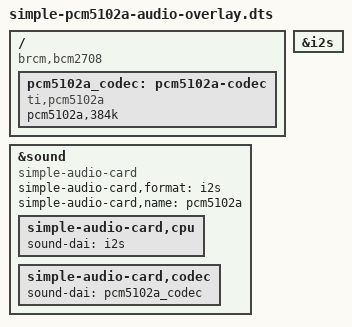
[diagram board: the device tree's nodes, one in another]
// Definitions for a generic board or HAT using TI PCM510x DAC
/dts-v1/;
/plugin/;

/ {
	compatible = "brcm,bcm2708";

	fragment@0 {
		target = <&i2s>;
		__overlay__ {
			status = "okay";
		};
	};

	fragment@1 {
		target-path = "/";
		__overlay__ {
			pcm5102a_codec: pcm5102a-codec {
				#sound-dai-cells = <0>;
				compatible = "ti,pcm5102a";
				pcm5102a,384k;
				status = "okay";
			};
		};
	};

	fragment@2 {
		target = <&sound>;
		simple_audio_card: __overlay__ {
			compatible = "simple-audio-card";
			simple-audio-card,format = "i2s";
			simple-audio-card,name = "pcm5102a";
			status = "okay";
			simple-audio-card,cpu {
				sound-dai = <&i2s>;
			};
			simple-audio-card,codec {
				sound-dai = <&pcm5102a_codec>;
			};
		};
	};

	__overrides__ {
		card_name = <&simple_audio_card>,"simple-audio-card,name";
	};
};
